# iostr912fa register map
Registers are 32-bit, access not given, no defined reset value unless marked. A register's access mark holds for its fields unless they carry their own. Addresses are absolute; registers are grouped by the start of their names; [hi:lo] are bit positions; {n}, {i} and the like mark numbered series; 'fields as' and 'values as' point back to an identical list.

## ENET
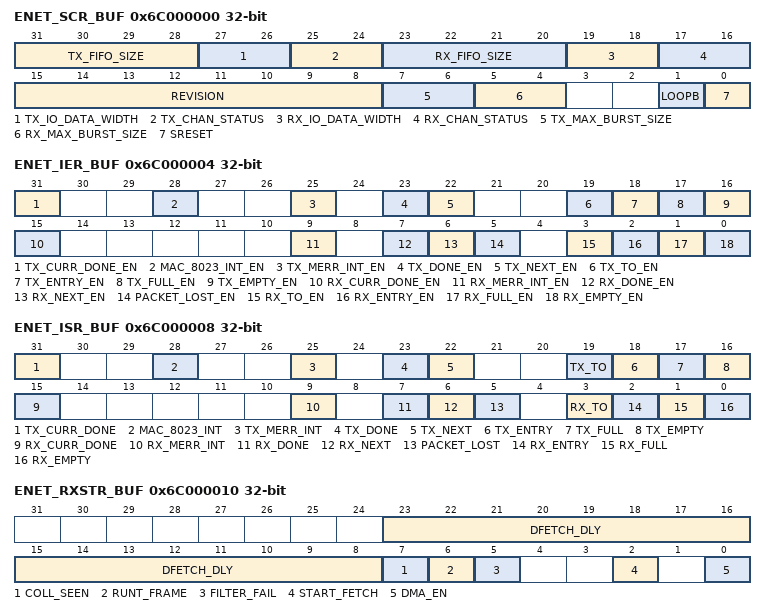
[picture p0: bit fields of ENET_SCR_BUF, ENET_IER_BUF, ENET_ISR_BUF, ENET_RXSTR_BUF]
0x6C000000 ENET_SCR_BUF
  [31:28] TX_FIFO_SIZE, [27:26] TX_IO_DATA_WIDTH, [25:24] TX_CHAN_STATUS, [23:20] RX_FIFO_SIZE, [19:18] RX_IO_DATA_WIDTH, [17:16] RX_CHAN_STATUS, [15:8] REVISION, [7:6] TX_MAX_BURST_SIZE, [5:4] RX_MAX_BURST_SIZE, [1] LOOPB, [0] SRESET
0x6C000004 ENET_IER_BUF
  [31] TX_CURR_DONE_EN, [28] MAC_8023_INT_EN, [25] TX_MERR_INT_EN, [23] TX_DONE_EN, [22] TX_NEXT_EN, [19] TX_TO_EN, [18] TX_ENTRY_EN, [17] TX_FULL_EN, [16] TX_EMPTY_EN, [15] RX_CURR_DONE_EN, [9] RX_MERR_INT_EN, [7] RX_DONE_EN, [6] RX_NEXT_EN, [5] PACKET_LOST_EN, [3] RX_TO_EN, [2] RX_ENTRY_EN, [1] RX_FULL_EN, [0] RX_EMPTY_EN
0x6C000008 ENET_ISR_BUF
  [31] TX_CURR_DONE, [28] MAC_8023_INT, [25] TX_MERR_INT, [23] TX_DONE, [22] TX_NEXT, [19] TX_TO, [18] TX_ENTRY, [17] TX_FULL, [16] TX_EMPTY, [15] RX_CURR_DONE, [9] RX_MERR_INT, [7] RX_DONE, [6] RX_NEXT, [5] PACKET_LOST, [3] RX_TO, [2] RX_ENTRY, [1] RX_FULL, [0] RX_EMPTY
0x6C00000C ENET_CCR_BUF
  [3:2] SEL_CLK
0x6C000010 ENET_RXSTR_BUF
  [23:8] DFETCH_DLY, [7] COLL_SEEN, [6] RUNT_FRAME, [5] FILTER_FAIL, [2] START_FETCH, [0] DMA_EN
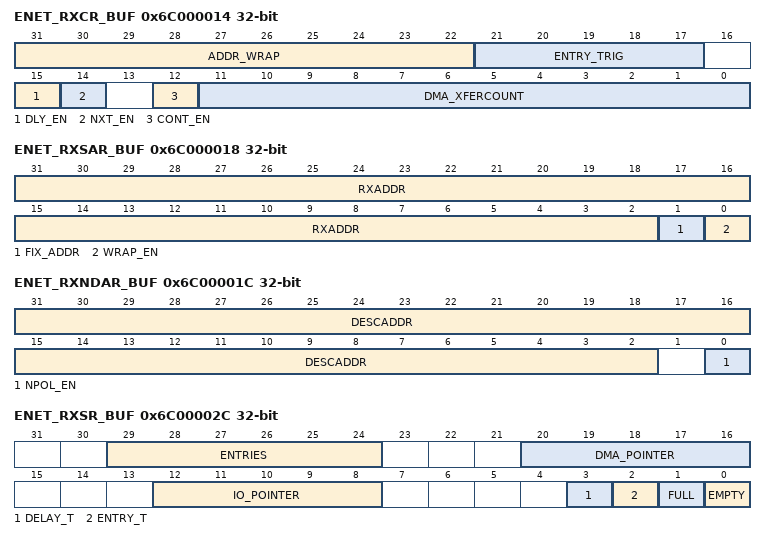
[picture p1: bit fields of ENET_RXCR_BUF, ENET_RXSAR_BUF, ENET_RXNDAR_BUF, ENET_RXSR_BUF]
0x6C000014 ENET_RXCR_BUF
  [31:22] ADDR_WRAP, [21:17] ENTRY_TRIG, [15] DLY_EN, [14] NXT_EN, [12] CONT_EN, [11:0] DMA_XFERCOUNT
0x6C000018 ENET_RXSAR_BUF
  [31:2] RXADDR, [1] FIX_ADDR, [0] WRAP_EN
0x6C00001C ENET_RXNDAR_BUF
  [31:2] DESCADDR, [0] NPOL_EN
0x6C000020 ENET_RXCAR_BUF
0x6C000024 ENET_RXCTCR_BUF
  [11:0] CXFER
0x6C000028 ENET_RXTOR_BUF
  [15:0] RXTO
0x6C00002C ENET_RXSR_BUF
  [29:24] ENTRIES, [20:16] DMA_POINTER, [12:8] IO_POINTER, [3] DELAY_T, [2] ENTRY_T, [1] FULL, [0] EMPTY
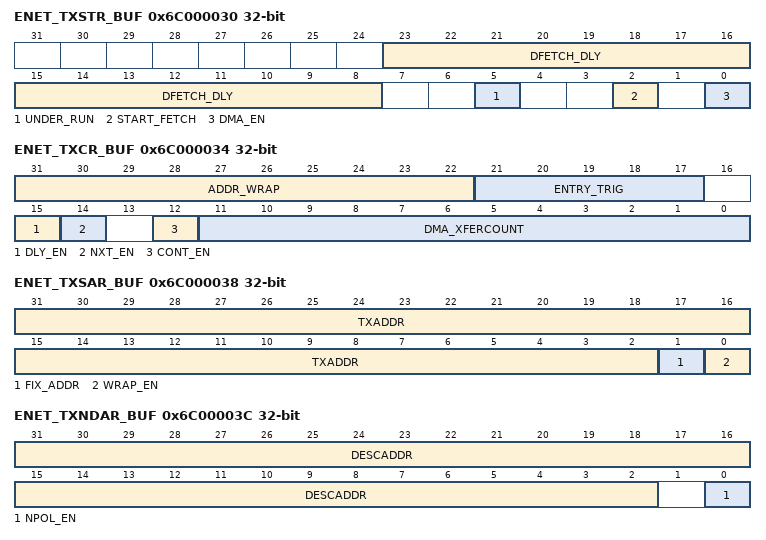
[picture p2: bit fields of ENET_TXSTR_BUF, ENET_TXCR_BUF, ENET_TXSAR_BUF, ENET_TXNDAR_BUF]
0x6C000030 ENET_TXSTR_BUF
  [23:8] DFETCH_DLY, [5] UNDER_RUN, [2] START_FETCH, [0] DMA_EN
0x6C000034 ENET_TXCR_BUF
  fields as ENET_RXCR_BUF
0x6C000038 ENET_TXSAR_BUF
  [31:2] TXADDR, [1] FIX_ADDR, [0] WRAP_EN
0x6C00003C ENET_TXNDAR_BUF
  [31:2] DESCADDR, [0] NPOL_EN
0x6C000040 ENET_TXCAR_BUF
0x6C000044 ENET_TXCTCR_BUF
  [11:0] CXFER
0x6C000048 ENET_TXTOR_BUF
  [15:0] TXTO
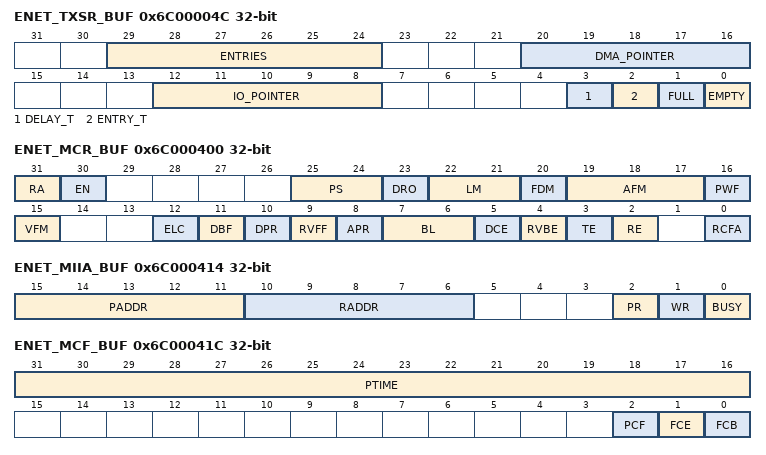
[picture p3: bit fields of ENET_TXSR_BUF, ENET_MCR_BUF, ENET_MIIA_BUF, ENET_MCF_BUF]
0x6C00004C ENET_TXSR_BUF
  fields as ENET_RXSR_BUF
{0x6C000100+4i} ENET_RX_FIFO_{i}_BUF (i=0..31)
{0x6C000200+4i} ENET_TX_FIFO_{i}_BUF (i=0..31)
0x6C000400 ENET_MCR_BUF
  [31] RA, [30] EN, [25:24] PS, [23] DRO, [22:21] LM, [20] FDM, [19:17] AFM, [16] PWF, [15] VFM, [12] ELC, [11] DBF, [10] DPR, [9] RVFF, [8] APR, [7:6] BL, [5] DCE, [4] RVBE, [3] TE, [2] RE, [0] RCFA
0x6C000404 ENET_MAH_BUF
0x6C000408 ENET_MAL_BUF
0x6C00040C ENET_MCHA_BUF
0x6C000410 ENET_MCLA_BUF
0x6C000414 ENET_MIIA_BUF
  [15:11] PADDR, [10:6] RADDR, [2] PR, [1] WR, [0] BUSY
0x6C000418 ENET_MIID_BUF
  [15:0] RDATA
0x6C00041C ENET_MCF_BUF
  [31:16] PTIME, [2] PCF, [1] FCE, [0] FCB
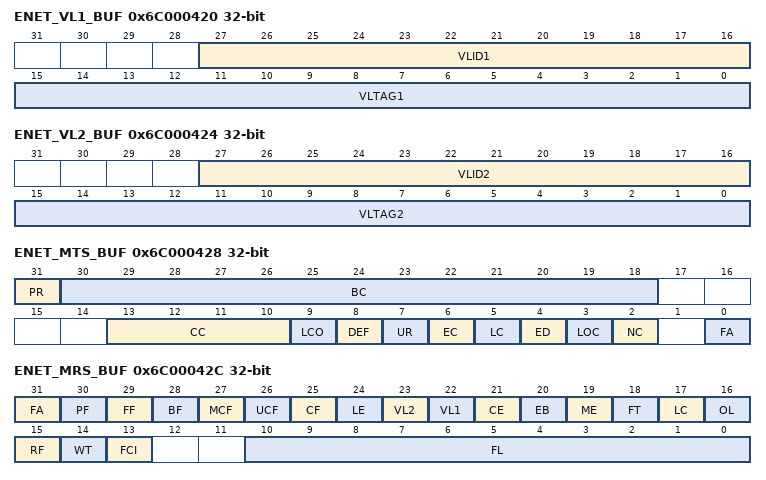
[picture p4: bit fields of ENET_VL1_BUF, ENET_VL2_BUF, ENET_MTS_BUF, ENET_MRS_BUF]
0x6C000420 ENET_VL1_BUF
  [27:16] VLID1, [15:0] VLTAG1
0x6C000424 ENET_VL2_BUF
  [27:16] VLID2, [15:0] VLTAG2
0x6C000428 ENET_MTS_BUF
  [31] PR, [30:18] BC, [13:10] CC, [9] LCO, [8] DEF, [7] UR, [6] EC, [5] LC, [4] ED, [3] LOC, [2] NC, [0] FA
0x6C00042C ENET_MRS_BUF
  [31] FA, [30] PF, [29] FF, [28] BF, [27] MCF, [26] UCF, [25] CF, [24] LE, [23] VL2, [22] VL1, [21] CE, [20] EB, [19] ME, [18] FT, [17] LC, [16] OL, [15] RF, [14] WT, [13] FCI, [10:0] FL
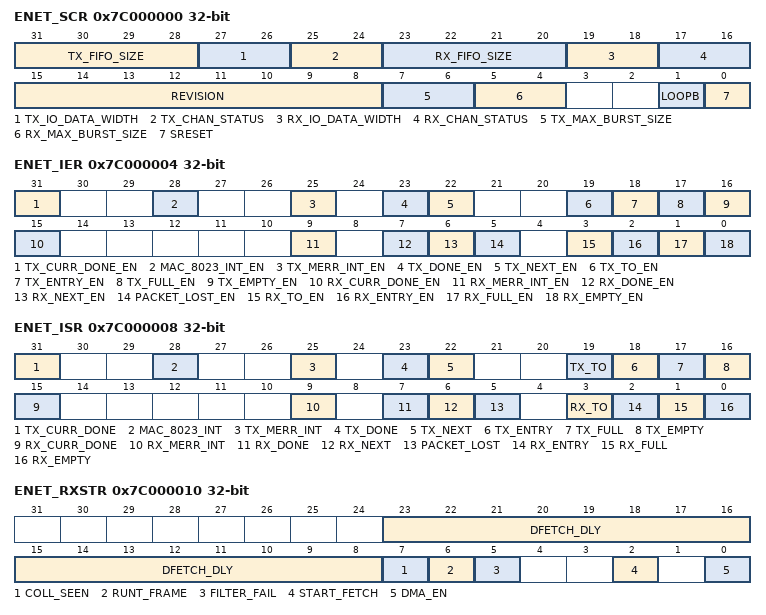
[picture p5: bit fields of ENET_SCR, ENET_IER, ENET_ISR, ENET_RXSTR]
0x7C000000 ENET_SCR
  fields as ENET_SCR_BUF
0x7C000004 ENET_IER
  fields as ENET_IER_BUF
0x7C000008 ENET_ISR
  fields as ENET_ISR_BUF
0x7C00000C ENET_CCR
  [3:2] SEL_CLK
0x7C000010 ENET_RXSTR
  fields as ENET_RXSTR_BUF
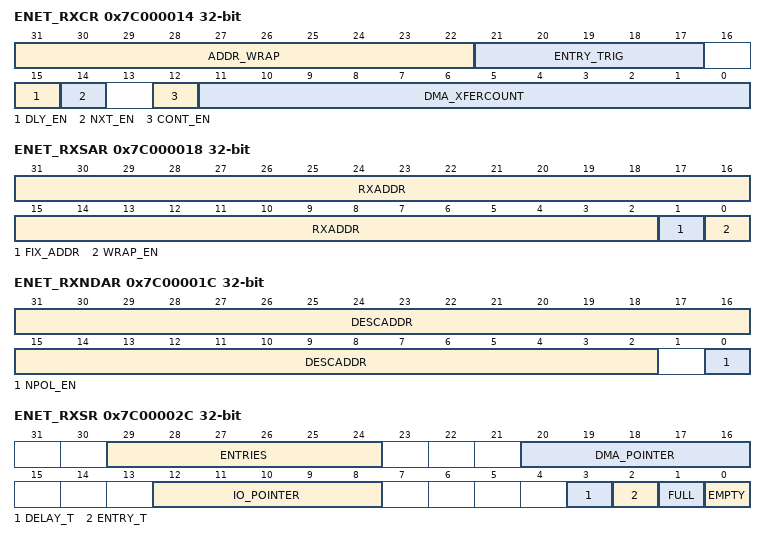
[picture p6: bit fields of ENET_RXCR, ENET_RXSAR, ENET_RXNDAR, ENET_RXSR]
0x7C000014 ENET_RXCR
  fields as ENET_RXCR_BUF
0x7C000018 ENET_RXSAR
  [31:2] RXADDR, [1] FIX_ADDR, [0] WRAP_EN
0x7C00001C ENET_RXNDAR
  [31:2] DESCADDR, [0] NPOL_EN
0x7C000020 ENET_RXCAR
0x7C000024 ENET_RXCTCR
  [11:0] CXFER
0x7C000028 ENET_RXTOR
  [15:0] RXTO
0x7C00002C ENET_RXSR
  fields as ENET_RXSR_BUF
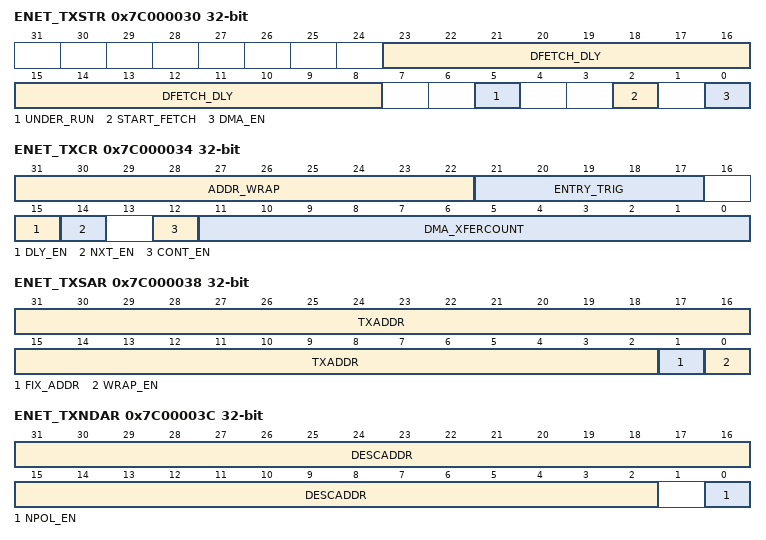
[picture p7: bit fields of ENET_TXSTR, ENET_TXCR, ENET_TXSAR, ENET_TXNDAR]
0x7C000030 ENET_TXSTR
  [23:8] DFETCH_DLY, [5] UNDER_RUN, [2] START_FETCH, [0] DMA_EN
0x7C000034 ENET_TXCR
  fields as ENET_RXCR_BUF
0x7C000038 ENET_TXSAR
  [31:2] TXADDR, [1] FIX_ADDR, [0] WRAP_EN
0x7C00003C ENET_TXNDAR
  [31:2] DESCADDR, [0] NPOL_EN
0x7C000040 ENET_TXCAR
0x7C000044 ENET_TXCTCR
  [11:0] CXFER
0x7C000048 ENET_TXTOR
  [15:0] TXTO
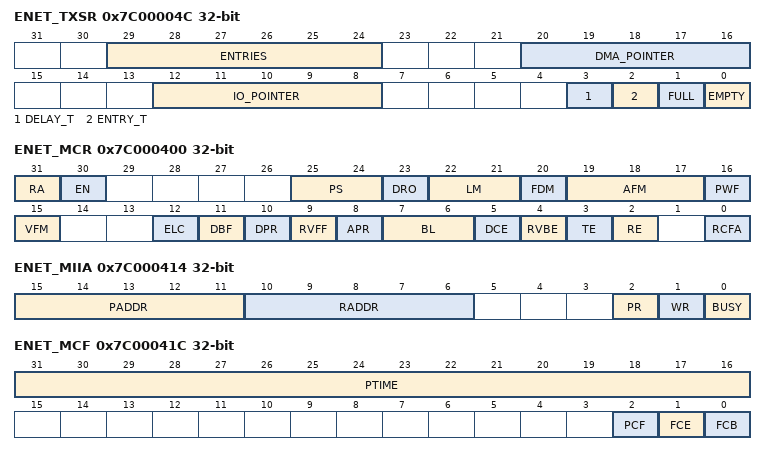
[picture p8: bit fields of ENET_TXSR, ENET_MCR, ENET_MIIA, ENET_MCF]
0x7C00004C ENET_TXSR
  fields as ENET_RXSR_BUF
{0x7C000100+4i} ENET_RX_FIFO_{i} (i=0..31)
{0x7C000200+4i} ENET_TX_FIFO_{i} (i=0..31)
0x7C000400 ENET_MCR
  fields as ENET_MCR_BUF
0x7C000404 ENET_MAH
0x7C000408 ENET_MAL
0x7C00040C ENET_MCHA
0x7C000410 ENET_MCLA
0x7C000414 ENET_MIIA
  [15:11] PADDR, [10:6] RADDR, [2] PR, [1] WR, [0] BUSY
0x7C000418 ENET_MIID
  [15:0] RDATA
0x7C00041C ENET_MCF
  [31:16] PTIME, [2] PCF, [1] FCE, [0] FCB
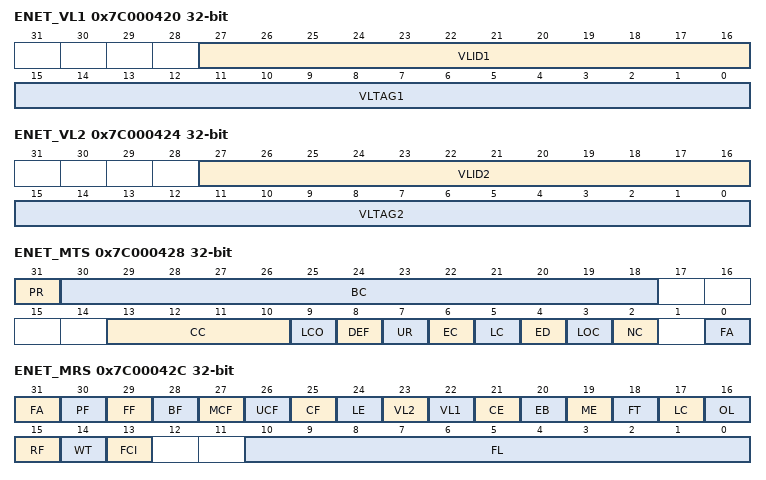
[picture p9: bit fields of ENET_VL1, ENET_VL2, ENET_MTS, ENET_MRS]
0x7C000420 ENET_VL1
  [27:16] VLID1, [15:0] VLTAG1
0x7C000424 ENET_VL2
  [27:16] VLID2, [15:0] VLTAG2
0x7C000428 ENET_MTS
  fields as ENET_MTS_BUF
0x7C00042C ENET_MRS
  fields as ENET_MRS_BUF
